VERSION "HIPBNYYYYYYYYYYYYYYYYYYYYYYYYYYYYYYYYYYYYY/4/%%%/4/'%**4YYY///"

NS_ :

BS_:

BU_:

BO_ 33 MagicCanNode1Heartbeat: 2 Vector__XXX
 SG_ MagicNode1Flags : 0|16@1+ (1,0) [0|0] "" Vector__XXX

BO_ 35 MagicCanNode2Heartbeat: 2 Vector__XXX
 SG_ MagicNode2Flags : 0|16@1+ (1,0) [0|0] "" Vector__XXX

BO_ 37 MagicCanNode3Heartbeat: 2 Vector__XXX
 SG_ MagicNode3Flags : 0|16@1+ (1,0) [0|0] "" Vector__XXX

BO_ 39 FrameFaultHeartbeat: 2 Vector__XXX
 SG_ FrameFaultFlags : 0|16@1+ (1,0) [0|0] "" Vector__XXX

BO_ 46 DriveControlsHeartbeat: 2 Vector__XXX
 SG_ DriveControlFlags : 0|16@1+ (1,0) [0|0] "" Vector__XXX

BO_ 47 MotorControllerHeartbeat: 2 Vector__XXX
 SG_ MotorControllerFlags : 0|16@1+ (1,0) [0|0] "" Vector__XXX

BO_ 49 CANMirrorHeatbeart: 2 Vector__XXX
 SG_ CANMirrorFlags : 0|16@1+ (1,0) [0|0] "" Vector__XXX

BO_ 52 RiderDisplayHeartbeat: 2 Vector__XXX
 SG_ RiderDisplayFlags : 0|16@1+ (1,0) [0|0] "" Vector__XXX

BO_ 58 BIM1Heartbeat: 2 Vector__XXX
 SG_ BIM1Flags : 0|16@1+ (1,0) [0|0] "" Vector__XXX

BO_ 60 BIM2Heartbeat: 2 Vector__XXX
 SG_ BIM2Flags : 0|16@1+ (1,0) [0|0] "" Vector__XXX

BO_ 62 BIM3Heartbeat: 2 Vector__XXX
 SG_ BIM3Flags : 0|16@1+ (1,0) [0|0] "" Vector__XXX

BO_ 66 BIM5Heartbeat: 2 Vector__XXX
 SG_ BIM5Flags : 0|16@1+ (1,0) [0|0] "" Vector__XXX

BO_ 68 BIM6Heartbeat: 2 Vector__XXX
 SG_ BIM6Flags : 0|16@1+ (1,0) [0|0] "" Vector__XXX

BO_ 70 BIM7Heartbeat: 2 Vector__XXX
 SG_ BIM7Flags : 0|16@1+ (1,0) [0|0] "" Vector__XXX

BO_ 72 BIM8Heartbeat: 2 Vector__XXX
 SG_ BIM8Flags : 0|16@1+ (1,0) [0|0] "" Vector__XXX

BO_ 74 BIM9Heartbeat: 2 Vector__XXX
 SG_ BIM9Flags : 0|16@1+ (1,0) [0|0] "" Vector__XXX

BO_ 76 BIM10Heartbeat: 2 Vector__XXX
 SG_ BIM10Flags : 0|16@1+ (1,0) [0|0] "" Vector__XXX

BO_ 78 BIM11Heartbeat: 2 Vector__XXX
 SG_ BIM11Flags : 0|16@1+ (1,0) [0|0] "" Vector__XXX

BO_ 80 BIM12Heartbeat: 2 Vector__XXX
 SG_ BIM12Flags : 0|16@1+ (1,0) [0|0] "" Vector__XXX

BO_ 256 FrameFaultDetectionStatus: 5 Vector__XXX
 SG_ EstimatedPackFrameResistance : 0|32@1- (1,0) [0|0] "(ohms)" Vector__XXX
 SG_ FrameFaultAlarmStatus : 32|8@1+ (1,0) [0|0] "" Vector__XXX

BO_ 257 FrontBrakePressure: 2 Vector__XXX
 SG_ FrontBrakePressure : 0|16@1+ (1,0) [0|0] "(kPa)" Vector__XXX

BO_ 258 RearBrakePressure: 2 Vector__XXX
 SG_ RearBrakePressure : 0|16@1+ (1,0) [0|0] "(kPa)" Vector__XXX

BO_ 259 FrontSuspensionTravel: 2 Vector__XXX
 SG_ FrontSuspensionPosition : 0|16@1+ (1,0) [0|0] "(%)" Vector__XXX

BO_ 260 RearSuspensionTravel: 2 Vector__XXX
 SG_ RearSuspensionPosition : 0|16@1+ (1,0) [0|0] "(%)" Vector__XXX

BO_ 261 BusSupplyCurrent12V: 0 Vector__XXX

BO_ 262 BusVoltage12V: 2 Vector__XXX
 SG_ BusVoltage12V : 0|16@1+ (1,0) [0|0] "(mv)" Vector__XXX

BO_ 263 PostMotorCoolantTemp: 2 Vector__XXX
 SG_ PostMotorCoolantTemp : 0|16@1- (1,0) [0|0] "(d°C)" Vector__XXX

BO_ 264 PostControllerCoolantTemp: 2 Vector__XXX
 SG_ PostControllerCoolantTemp : 0|16@1- (1,0) [0|0] "(d°C)" Vector__XXX

BO_ 265 RadiatorCoolSideCoolantTemp: 2 Vector__XXX
 SG_ RadiatorCoolSideCoolantTemp : 0|16@1- (1,0) [0|0] "(d°C)" Vector__XXX

BO_ 266 AmbientTemp: 2 Vector__XXX
 SG_ AmbientTemp : 0|16@1- (1,0) [0|0] "(d°C)" Vector__XXX

BO_ 267 GPSLatAndValidityStatus: 8 Vector__XXX
 SG_ GPSLatitude : 0|56@1- (1,0) [0|0] "" Vector__XXX
 SG_ GPSValidityStatus : 56|8@1+ (1,0) [0|0] "" Vector__XXX

BO_ 268 GPSLongitude: 7 Vector__XXX
 SG_ GPSLongitude : 0|56@1- (1,0) [0|0] "" Vector__XXX

BO_ 269 GPSAltitudeAndAccuracy: 8 Vector__XXX
 SG_ GPSAltitude : 0|48@1- (1,0) [0|0] "(decimeters)" Vector__XXX
 SG_ PositionDOP : 48|16@1+ (1,0) [0|0] "" Vector__XXX

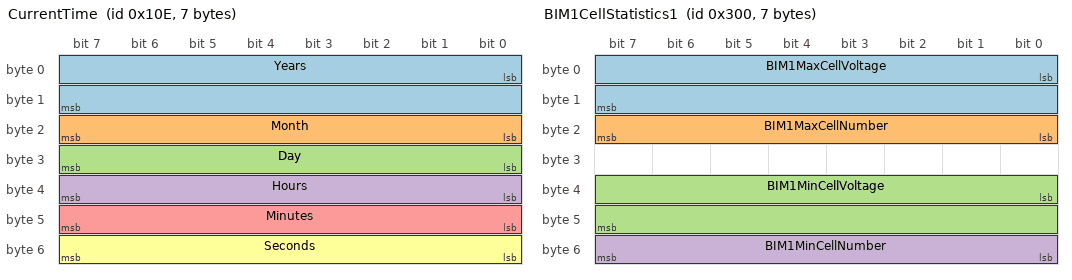
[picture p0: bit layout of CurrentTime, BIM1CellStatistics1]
BO_ 270 CurrentTime: 7 Vector__XXX
 SG_ Years : 0|16@1+ (1,0) [0|0] "" Vector__XXX
 SG_ Month : 16|8@1+ (1,0) [0|0] "" Vector__XXX
 SG_ Day : 24|8@1+ (1,0) [0|0] "" Vector__XXX
 SG_ Hours : 32|8@1+ (1,0) [0|0] "" Vector__XXX
 SG_ Minutes : 40|8@1+ (1,0) [0|0] "" Vector__XXX
 SG_ Seconds : 48|8@1+ (1,0) [0|0] "" Vector__XXX

BO_ 271 IMUAccelerationMeasurement: 6 Vector__XXX
 SG_ XAxisAcceleration : 0|16@1- (1,0) [0|0] "(?)" Vector__XXX
 SG_ YAxisAcceleration : 16|16@1- (1,0) [0|0] "(?)" Vector__XXX
 SG_ ZAxisAcceleration : 32|16@1- (1,0) [0|0] "(?)" Vector__XXX

BO_ 272 IMUGyroMeasurement: 6 Vector__XXX
 SG_ XAxisRoll : 0|16@1- (1,0) [0|0] "(?)" Vector__XXX
 SG_ YAxisRoll : 16|16@1- (1,0) [0|0] "(?)" Vector__XXX
 SG_ ZAxisRoll : 32|16@1- (1,0) [0|0] "(?)" Vector__XXX

BO_ 273 MotorPlateTemp: 8 Vector__XXX
 SG_ MotorPlateTemp1 : 0|16@1- (1,0) [0|0] "(dºC)" Vector__XXX
 SG_ MotorPlateTemp2 : 16|16@1- (1,0) [0|0] "(dºC)" Vector__XXX

BO_ 768 BIM1CellStatistics1: 7 Vector__XXX
 SG_ BIM1MaxCellVoltage : 0|16@1+ (1,0) [0|0] "(mV)" Vector__XXX
 SG_ BIM1MaxCellNumber : 16|8@1+ (1,0) [0|0] "" Vector__XXX
 SG_ BIM1MinCellVoltage : 32|16@1+ (1,0) [0|0] "(mV)" Vector__XXX
 SG_ BIM1MinCellNumber : 48|8@1+ (1,0) [0|0] "" Vector__XXX

BO_ 769 BIM1CellStatistics2: 5 Vector__XXX
 SG_ BIM1AvgCellVoltage : 0|16@1+ (1,0) [0|0] "(mV)" Vector__XXX
 SG_ BIM1StdevCellVoltage : 16|16@1+ (1,0) [0|0] "(mV)" Vector__XXX
 SG_ BIM1NumberBalancingCells : 32|8@1+ (1,0) [0|0] "" Vector__XXX

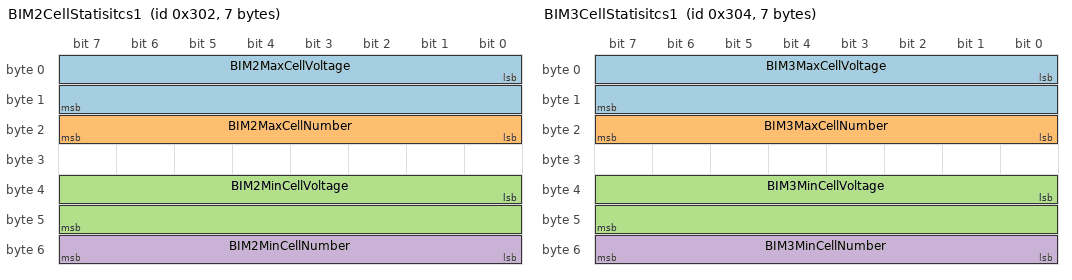
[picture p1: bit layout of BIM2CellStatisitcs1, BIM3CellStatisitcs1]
BO_ 770 BIM2CellStatisitcs1: 7 Vector__XXX
 SG_ BIM2MaxCellVoltage : 0|16@1+ (1,0) [0|0] "(mV)" Vector__XXX
 SG_ BIM2MaxCellNumber : 16|8@1+ (1,0) [0|0] "" Vector__XXX
 SG_ BIM2MinCellVoltage : 32|16@1+ (1,0) [0|0] "(mV)" Vector__XXX
 SG_ BIM2MinCellNumber : 48|8@1+ (1,0) [0|0] "" Vector__XXX

BO_ 771 BIM2CellStatistics2: 5 Vector__XXX
 SG_ BIM2AvgCellVoltage : 0|16@1+ (1,0) [0|0] "(mV)" Vector__XXX
 SG_ BIM2StdevCellVoltage : 16|16@1+ (1,0) [0|0] "(mV)" Vector__XXX
 SG_ BIM2NumberBalancingCells : 32|8@1+ (1,0) [0|0] "" Vector__XXX

BO_ 772 BIM3CellStatisitcs1: 7 Vector__XXX
 SG_ BIM3MaxCellVoltage : 0|16@1+ (1,0) [0|0] "(mV)" Vector__XXX
 SG_ BIM3MaxCellNumber : 16|8@1+ (1,0) [0|0] "" Vector__XXX
 SG_ BIM3MinCellVoltage : 32|16@1+ (1,0) [0|0] "(mV)" Vector__XXX
 SG_ BIM3MinCellNumber : 48|8@1+ (1,0) [0|0] "" Vector__XXX

BO_ 773 BIM3CellStatistics2: 5 Vector__XXX
 SG_ BIM3AvgCellVoltage : 0|16@1+ (1,0) [0|0] "(mV)" Vector__XXX
 SG_ BIM3StdevCellVoltage : 16|16@1+ (1,0) [0|0] "(mV)" Vector__XXX
 SG_ BIM3NumberBalancingCells : 32|8@1+ (1,0) [0|0] "" Vector__XXX

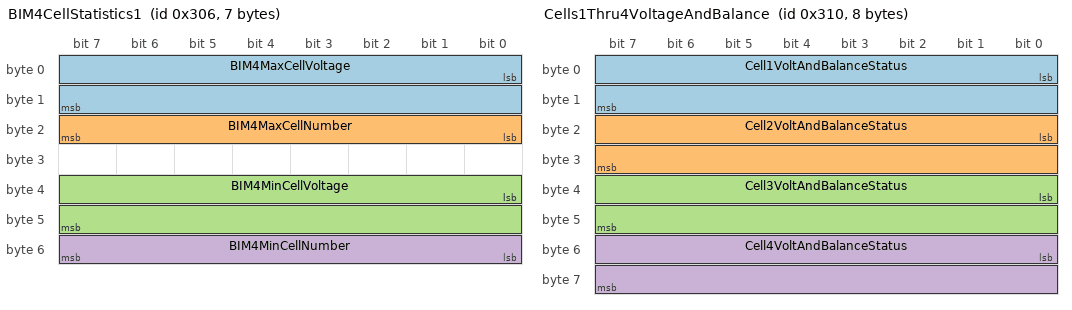
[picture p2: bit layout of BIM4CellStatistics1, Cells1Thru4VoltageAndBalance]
BO_ 774 BIM4CellStatistics1: 7 Vector__XXX
 SG_ BIM4MaxCellVoltage : 0|16@1+ (1,0) [0|0] "(mV)" Vector__XXX
 SG_ BIM4MaxCellNumber : 16|8@1+ (1,0) [0|0] "" Vector__XXX
 SG_ BIM4MinCellVoltage : 32|16@1+ (1,0) [0|0] "(mV)" Vector__XXX
 SG_ BIM4MinCellNumber : 48|8@1+ (1,0) [0|0] "" Vector__XXX

BO_ 775 BIM4CellStatistics2: 5 Vector__XXX
 SG_ BIM4AvgCellVoltage : 0|16@1+ (1,0) [0|0] "(mV)" Vector__XXX
 SG_ BIM4StdevCellVoltage : 16|16@1+ (1,0) [0|0] "(mV)" Vector__XXX
 SG_ BIM4NumberBalancingCells : 32|8@1+ (1,0) [0|0] "" Vector__XXX

BO_ 784 Cells1Thru4VoltageAndBalance: 8 Vector__XXX
 SG_ Cell1VoltAndBalanceStatus : 0|16@1- (1,0) [0|0] "(mV and sign)" Vector__XXX
 SG_ Cell2VoltAndBalanceStatus : 16|16@1- (1,0) [0|0] "(mV and sign)" Vector__XXX
 SG_ Cell3VoltAndBalanceStatus : 32|16@1- (1,0) [0|0] "(mV and sign)" Vector__XXX
 SG_ Cell4VoltAndBalanceStatus : 48|16@1- (1,0) [0|0] "(mV and sign)" Vector__XXX

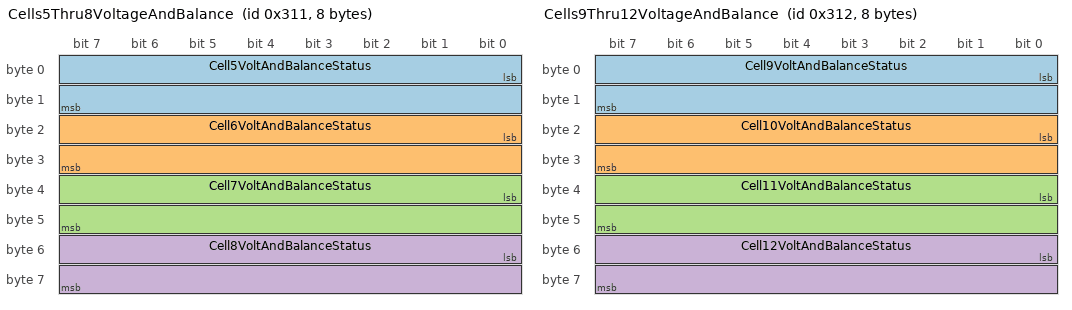
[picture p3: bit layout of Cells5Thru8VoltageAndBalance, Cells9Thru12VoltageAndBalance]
BO_ 785 Cells5Thru8VoltageAndBalance: 8 Vector__XXX
 SG_ Cell5VoltAndBalanceStatus : 0|16@1- (1,0) [0|0] "(mV and sign)" Vector__XXX
 SG_ Cell6VoltAndBalanceStatus : 16|16@1- (1,0) [0|0] "(mV and sign)" Vector__XXX
 SG_ Cell7VoltAndBalanceStatus : 32|16@1- (1,0) [0|0] "(mV and sign)" Vector__XXX
 SG_ Cell8VoltAndBalanceStatus : 48|16@1- (1,0) [0|0] "(mV and sign)" Vector__XXX

BO_ 786 Cells9Thru12VoltageAndBalance: 8 Vector__XXX
 SG_ Cell9VoltAndBalanceStatus : 0|16@1- (1,0) [0|0] "(mV and sign)" Vector__XXX
 SG_ Cell10VoltAndBalanceStatus : 16|16@1- (1,0) [0|0] "(mV and sign)" Vector__XXX
 SG_ Cell11VoltAndBalanceStatus : 32|16@1- (1,0) [0|0] "(mV and sign)" Vector__XXX
 SG_ Cell12VoltAndBalanceStatus : 48|16@1- (1,0) [0|0] "(mV and sign)" Vector__XXX

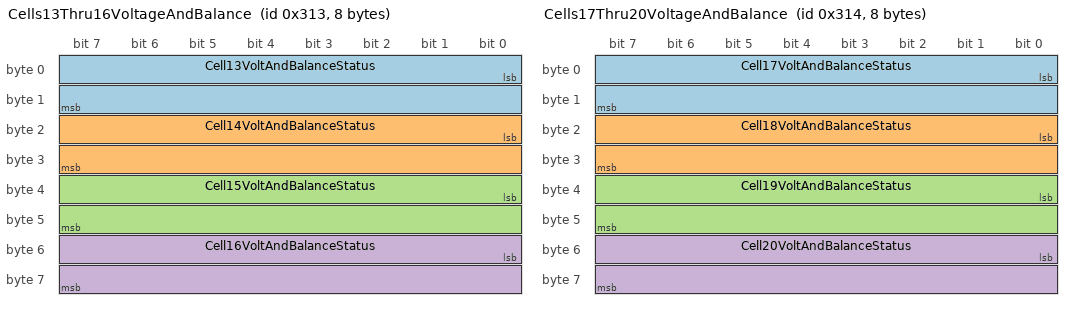
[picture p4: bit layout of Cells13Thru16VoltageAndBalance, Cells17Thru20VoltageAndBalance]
BO_ 787 Cells13Thru16VoltageAndBalance: 8 Vector__XXX
 SG_ Cell13VoltAndBalanceStatus : 0|16@1- (1,0) [0|0] "(mV and sign)" Vector__XXX
 SG_ Cell14VoltAndBalanceStatus : 16|16@1- (1,0) [0|0] "(mV and sign)" Vector__XXX
 SG_ Cell15VoltAndBalanceStatus : 32|16@1- (1,0) [0|0] "(mV and sign)" Vector__XXX
 SG_ Cell16VoltAndBalanceStatus : 48|16@1- (1,0) [0|0] "(mV and sign)" Vector__XXX

BO_ 788 Cells17Thru20VoltageAndBalance: 8 Vector__XXX
 SG_ Cell17VoltAndBalanceStatus : 0|16@1- (1,0) [0|0] "(mV and sign)" Vector__XXX
 SG_ Cell18VoltAndBalanceStatus : 16|16@1- (1,0) [0|0] "(mV and sign)" Vector__XXX
 SG_ Cell19VoltAndBalanceStatus : 32|16@1- (0,0) [0|0] "(mV and sign)" Vector__XXX
 SG_ Cell20VoltAndBalanceStatus : 48|16@1- (1,0) [0|0] "(mV and sign)" Vector__XXX

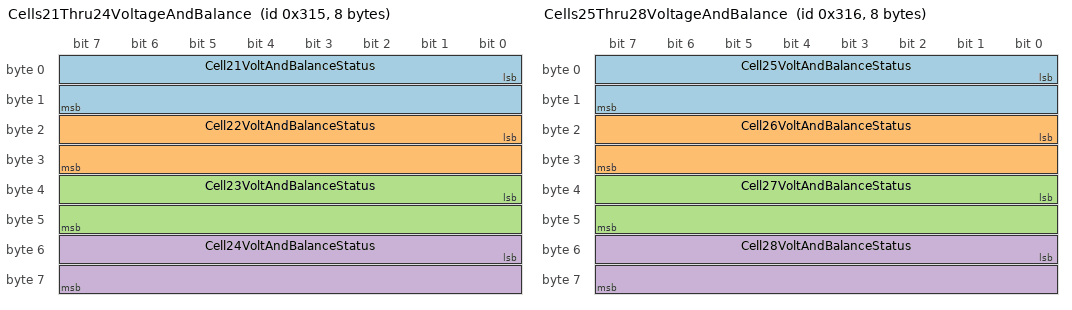
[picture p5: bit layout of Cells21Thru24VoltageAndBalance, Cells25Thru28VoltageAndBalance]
BO_ 789 Cells21Thru24VoltageAndBalance: 8 Vector__XXX
 SG_ Cell21VoltAndBalanceStatus : 0|16@1- (1,0) [0|0] "(mV and sign)" Vector__XXX
 SG_ Cell22VoltAndBalanceStatus : 16|16@1- (1,0) [0|0] "(mV and sign)" Vector__XXX
 SG_ Cell23VoltAndBalanceStatus : 32|16@1- (1,0) [0|0] "(mV and sign)" Vector__XXX
 SG_ Cell24VoltAndBalanceStatus : 48|16@1- (1,0) [0|0] "(mV and sign)" Vector__XXX

BO_ 790 Cells25Thru28VoltageAndBalance: 8 Vector__XXX
 SG_ Cell25VoltAndBalanceStatus : 0|16@1- (1,0) [0|0] "(mV and sign)" Vector__XXX
 SG_ Cell26VoltAndBalanceStatus : 16|16@1- (1,0) [0|0] "(mV and sign)" Vector__XXX
 SG_ Cell27VoltAndBalanceStatus : 32|16@1- (1,0) [0|0] "(mV and sign)" Vector__XXX
 SG_ Cell28VoltAndBalanceStatus : 48|16@1- (1,0) [0|0] "(mV and sign)" Vector__XXX

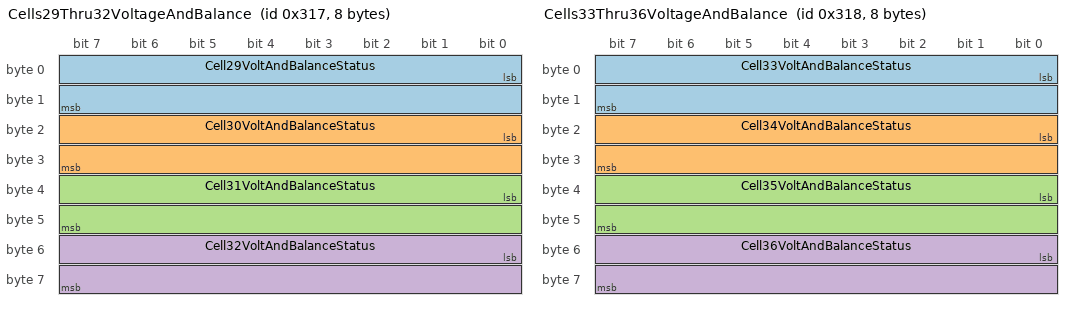
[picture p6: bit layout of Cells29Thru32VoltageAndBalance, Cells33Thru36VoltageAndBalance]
BO_ 791 Cells29Thru32VoltageAndBalance: 8 Vector__XXX
 SG_ Cell29VoltAndBalanceStatus : 0|16@1- (1,0) [0|0] "(mV and sign)" Vector__XXX
 SG_ Cell30VoltAndBalanceStatus : 16|16@1- (1,0) [0|0] "(mV and sign)" Vector__XXX
 SG_ Cell31VoltAndBalanceStatus : 32|16@1- (1,0) [0|0] "(mV and sign)" Vector__XXX
 SG_ Cell32VoltAndBalanceStatus : 48|16@1- (1,0) [0|0] "(mV and sign)" Vector__XXX

BO_ 792 Cells33Thru36VoltageAndBalance: 8 Vector__XXX
 SG_ Cell33VoltAndBalanceStatus : 0|16@1- (1,0) [0|0] "(mV and sign)" Vector__XXX
 SG_ Cell34VoltAndBalanceStatus : 16|16@1- (1,0) [0|0] "(mV and sign)" Vector__XXX
 SG_ Cell35VoltAndBalanceStatus : 32|16@1- (1,0) [0|0] "(mV and sign)" Vector__XXX
 SG_ Cell36VoltAndBalanceStatus : 48|16@1- (1,0) [0|0] "(mV and sign)" Vector__XXX

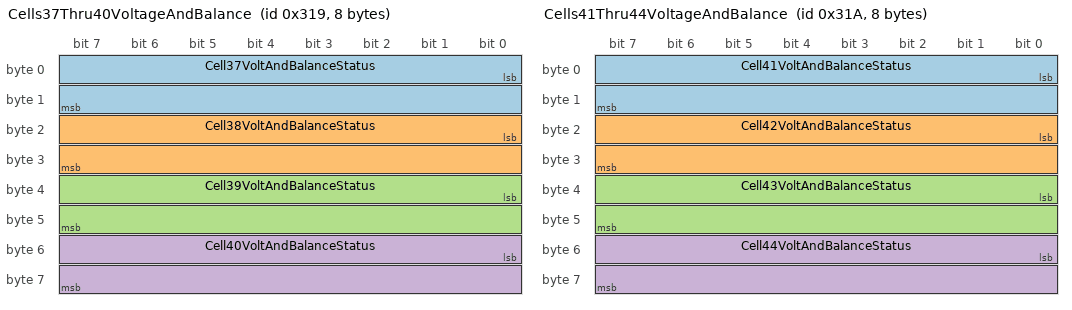
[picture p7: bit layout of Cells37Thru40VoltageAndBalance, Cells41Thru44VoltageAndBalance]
BO_ 793 Cells37Thru40VoltageAndBalance: 8 Vector__XXX
 SG_ Cell37VoltAndBalanceStatus : 0|16@1- (1,0) [0|0] "(mV and sign)" Vector__XXX
 SG_ Cell38VoltAndBalanceStatus : 16|16@1- (1,0) [0|0] "(mV and sign)" Vector__XXX
 SG_ Cell39VoltAndBalanceStatus : 32|16@1- (1,0) [0|0] "(mV and sign)" Vector__XXX
 SG_ Cell40VoltAndBalanceStatus : 48|16@1- (1,0) [0|0] "(mV and sign)" Vector__XXX

BO_ 794 Cells41Thru44VoltageAndBalance: 8 Vector__XXX
 SG_ Cell41VoltAndBalanceStatus : 0|16@1- (1,0) [0|0] "(mV and sign)" Vector__XXX
 SG_ Cell42VoltAndBalanceStatus : 16|16@1- (1,0) [0|0] "(mV and sign)" Vector__XXX
 SG_ Cell43VoltAndBalanceStatus : 32|16@1- (1,0) [0|0] "(mV and sign)" Vector__XXX
 SG_ Cell44VoltAndBalanceStatus : 48|16@1- (1,0) [0|0] "(mV and sign)" Vector__XXX

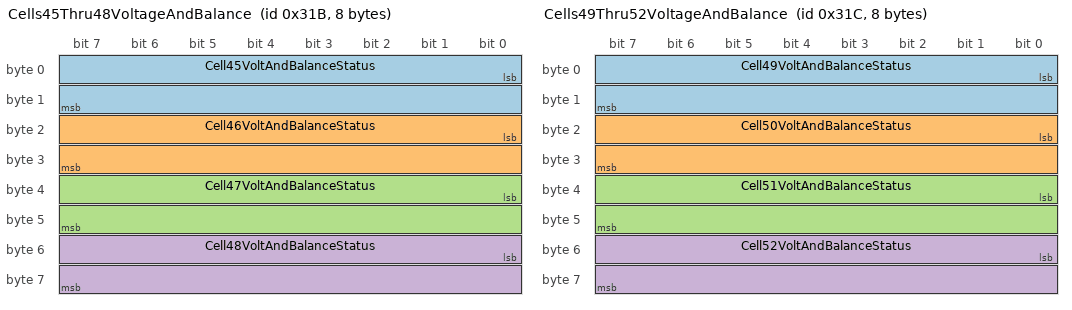
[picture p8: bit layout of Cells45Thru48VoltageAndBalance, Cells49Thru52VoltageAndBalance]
BO_ 795 Cells45Thru48VoltageAndBalance: 8 Vector__XXX
 SG_ Cell45VoltAndBalanceStatus : 0|16@1- (1,0) [0|0] "(mV and sign)" Vector__XXX
 SG_ Cell46VoltAndBalanceStatus : 16|16@1- (1,0) [0|0] "(mV and sign)" Vector__XXX
 SG_ Cell47VoltAndBalanceStatus : 32|16@1- (1,0) [0|0] "(mV and sign)" Vector__XXX
 SG_ Cell48VoltAndBalanceStatus : 48|16@1- (1,0) [0|0] "(mV and sign)" Vector__XXX

BO_ 796 Cells49Thru52VoltageAndBalance: 8 Vector__XXX
 SG_ Cell49VoltAndBalanceStatus : 0|16@1- (1,0) [0|0] "(mV and sign)" Vector__XXX
 SG_ Cell50VoltAndBalanceStatus : 16|16@1- (1,0) [0|0] "(mV and sign)" Vector__XXX
 SG_ Cell51VoltAndBalanceStatus : 32|16@1- (1,0) [0|0] "(mV and sign)" Vector__XXX
 SG_ Cell52VoltAndBalanceStatus : 48|16@1- (1,0) [0|0] "(mV and sign)" Vector__XXX

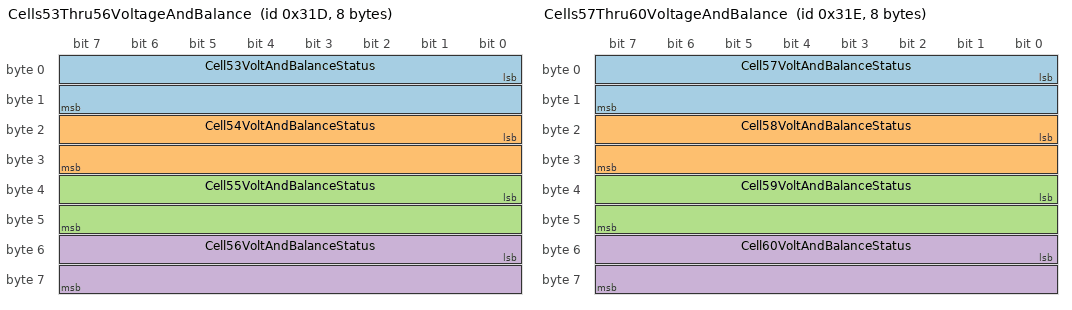
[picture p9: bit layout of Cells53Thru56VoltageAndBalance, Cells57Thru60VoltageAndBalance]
BO_ 797 Cells53Thru56VoltageAndBalance: 8 Vector__XXX
 SG_ Cell53VoltAndBalanceStatus : 0|16@1- (1,0) [0|0] "(mV and sign)" Vector__XXX
 SG_ Cell54VoltAndBalanceStatus : 16|16@1- (1,0) [0|0] "(mV and sign)" Vector__XXX
 SG_ Cell55VoltAndBalanceStatus : 32|16@1- (1,0) [0|0] "(mV and sign)" Vector__XXX
 SG_ Cell56VoltAndBalanceStatus : 48|16@1- (1,0) [0|0] "(mV and sign)" Vector__XXX

BO_ 798 Cells57Thru60VoltageAndBalance: 8 Vector__XXX
 SG_ Cell57VoltAndBalanceStatus : 0|16@1- (1,0) [0|0] "(mV and sign)" Vector__XXX
 SG_ Cell58VoltAndBalanceStatus : 16|16@1- (1,0) [0|0] "(mV and sign)" Vector__XXX
 SG_ Cell59VoltAndBalanceStatus : 32|16@1- (1,0) [0|0] "(mV and sign)" Vector__XXX
 SG_ Cell60VoltAndBalanceStatus : 48|16@1- (1,0) [0|0] "(mV and sign)" Vector__XXX

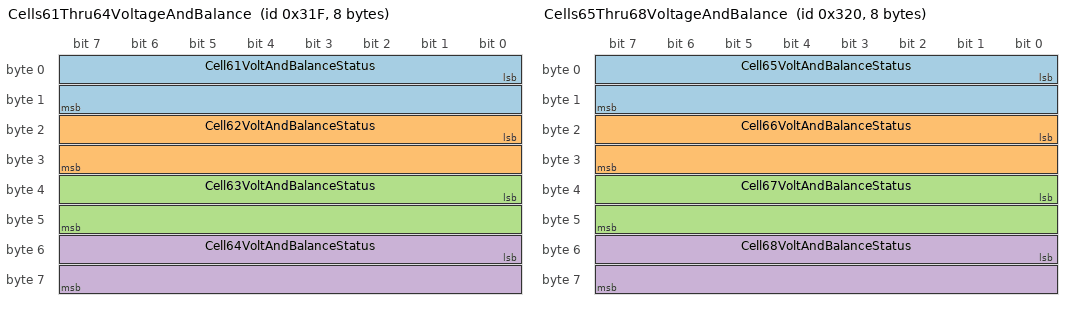
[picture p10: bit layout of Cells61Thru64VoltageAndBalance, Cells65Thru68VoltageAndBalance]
BO_ 799 Cells61Thru64VoltageAndBalance: 8 Vector__XXX
 SG_ Cell61VoltAndBalanceStatus : 0|16@1- (1,0) [0|0] "(mV and sign)" Vector__XXX
 SG_ Cell62VoltAndBalanceStatus : 16|16@1- (1,0) [0|0] "(mV and sign)" Vector__XXX
 SG_ Cell63VoltAndBalanceStatus : 32|16@1- (1,0) [0|0] "(mV and sign)" Vector__XXX
 SG_ Cell64VoltAndBalanceStatus : 48|16@1- (1,0) [0|0] "(mV and sign)" Vector__XXX

BO_ 800 Cells65Thru68VoltageAndBalance: 8 Vector__XXX
 SG_ Cell65VoltAndBalanceStatus : 0|16@1- (1,0) [0|0] "(mV and sign)" Vector__XXX
 SG_ Cell66VoltAndBalanceStatus : 16|16@1- (1,0) [0|0] "(mV and sign)" Vector__XXX
 SG_ Cell67VoltAndBalanceStatus : 32|16@1- (1,0) [0|0] "(mV and sign)" Vector__XXX
 SG_ Cell68VoltAndBalanceStatus : 48|16@1- (1,0) [0|0] "(mV and sign)" Vector__XXX

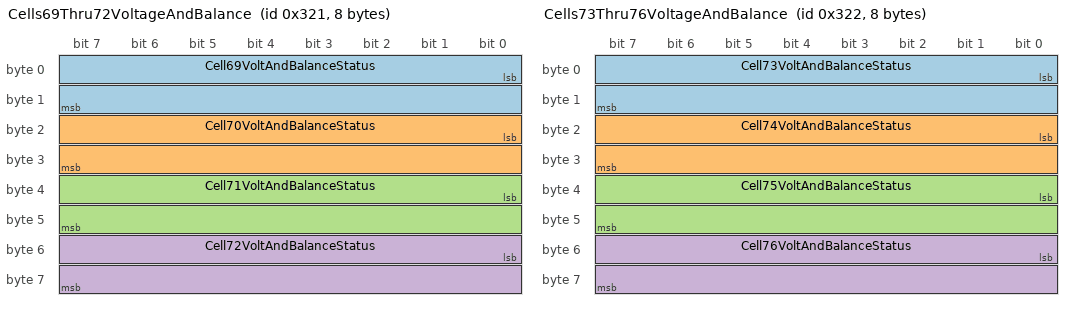
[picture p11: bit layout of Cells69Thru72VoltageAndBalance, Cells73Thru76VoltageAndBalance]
BO_ 801 Cells69Thru72VoltageAndBalance: 8 Vector__XXX
 SG_ Cell69VoltAndBalanceStatus : 0|16@1- (1,0) [0|0] "(mV and sign)" Vector__XXX
 SG_ Cell70VoltAndBalanceStatus : 16|16@1- (1,0) [0|0] "(mV and sign)" Vector__XXX
 SG_ Cell71VoltAndBalanceStatus : 32|16@1- (1,0) [0|0] "(mV and sign)" Vector__XXX
 SG_ Cell72VoltAndBalanceStatus : 48|16@1- (1,0) [0|0] "(mV and sign)" Vector__XXX

BO_ 802 Cells73Thru76VoltageAndBalance: 8 Vector__XXX
 SG_ Cell73VoltAndBalanceStatus : 0|16@1- (1,0) [0|0] "(mV and sign)" Vector__XXX
 SG_ Cell74VoltAndBalanceStatus : 16|16@1- (1,0) [0|0] "(mV and sign)" Vector__XXX
 SG_ Cell75VoltAndBalanceStatus : 32|16@1- (1,0) [0|0] "(mV and sign)" Vector__XXX
 SG_ Cell76VoltAndBalanceStatus : 48|16@1- (1,0) [0|0] "(mV and sign)" Vector__XXX

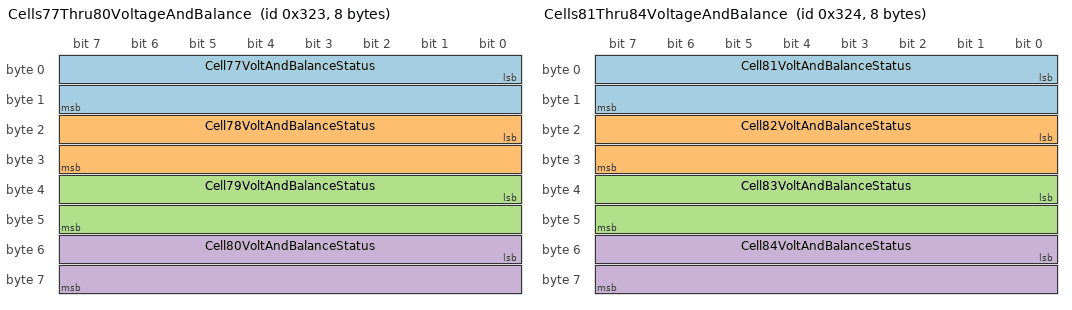
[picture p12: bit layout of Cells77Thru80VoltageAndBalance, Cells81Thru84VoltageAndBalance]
BO_ 803 Cells77Thru80VoltageAndBalance: 8 Vector__XXX
 SG_ Cell77VoltAndBalanceStatus : 0|16@1- (1,0) [0|0] "(mV and sign)" Vector__XXX
 SG_ Cell78VoltAndBalanceStatus : 16|16@1- (1,0) [0|0] "(mV and sign)" Vector__XXX
 SG_ Cell79VoltAndBalanceStatus : 32|16@1- (1,0) [0|0] "(mV and sign)" Vector__XXX
 SG_ Cell80VoltAndBalanceStatus : 48|16@1- (1,0) [0|0] "(mV and sign)" Vector__XXX

BO_ 804 Cells81Thru84VoltageAndBalance: 8 Vector__XXX
 SG_ Cell81VoltAndBalanceStatus : 0|16@1- (1,0) [0|0] "(mV and sign)" Vector__XXX
 SG_ Cell82VoltAndBalanceStatus : 16|16@1- (1,0) [0|0] "(mV and sign)" Vector__XXX
 SG_ Cell83VoltAndBalanceStatus : 32|16@1- (1,0) [0|0] "(mV and sign)" Vector__XXX
 SG_ Cell84VoltAndBalanceStatus : 48|16@1- (1,0) [0|0] "(mV and sign)" Vector__XXX

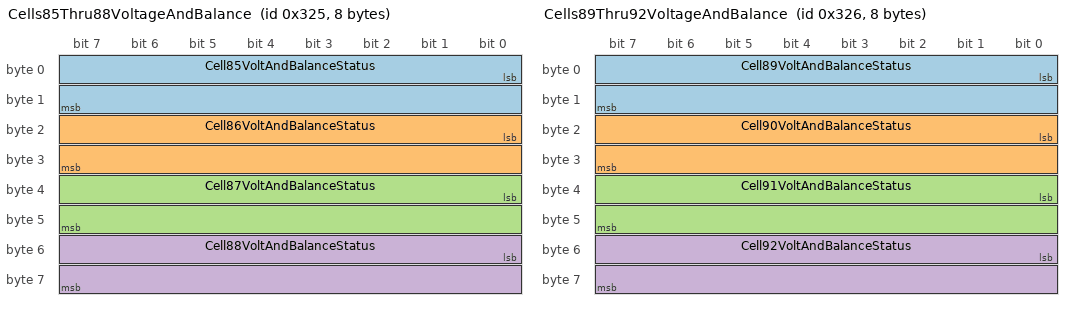
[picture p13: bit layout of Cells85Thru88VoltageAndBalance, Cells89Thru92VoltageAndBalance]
BO_ 805 Cells85Thru88VoltageAndBalance: 8 Vector__XXX
 SG_ Cell85VoltAndBalanceStatus : 0|16@1- (1,0) [0|0] "(mV and sign)" Vector__XXX
 SG_ Cell86VoltAndBalanceStatus : 16|16@1- (1,0) [0|0] "(mV and sign)" Vector__XXX
 SG_ Cell87VoltAndBalanceStatus : 32|16@1- (1,0) [0|0] "(mV and sign)" Vector__XXX
 SG_ Cell88VoltAndBalanceStatus : 48|16@1- (1,0) [0|0] "(mV and sign)" Vector__XXX

BO_ 806 Cells89Thru92VoltageAndBalance: 8 Vector__XXX
 SG_ Cell89VoltAndBalanceStatus : 0|16@1- (1,0) [0|0] "(mV and sign)" Vector__XXX
 SG_ Cell90VoltAndBalanceStatus : 16|16@1- (1,0) [0|0] "(mV and sign)" Vector__XXX
 SG_ Cell91VoltAndBalanceStatus : 32|16@1- (1,0) [0|0] "(mV and sign)" Vector__XXX
 SG_ Cell92VoltAndBalanceStatus : 48|16@1- (1,0) [0|0] "(mV and sign)" Vector__XXX

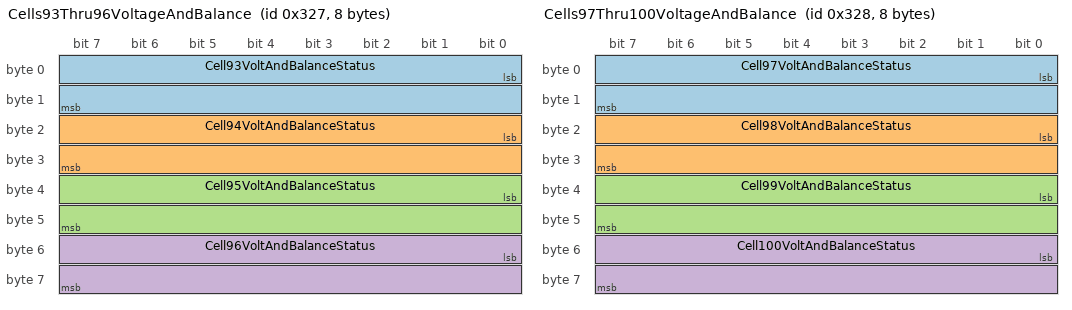
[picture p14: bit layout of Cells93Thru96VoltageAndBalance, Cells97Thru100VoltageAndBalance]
BO_ 807 Cells93Thru96VoltageAndBalance: 8 Vector__XXX
 SG_ Cell93VoltAndBalanceStatus : 0|16@1- (1,0) [0|0] "(mV and sign)" Vector__XXX
 SG_ Cell94VoltAndBalanceStatus : 16|16@1- (1,0) [0|0] "(mV and sign)" Vector__XXX
 SG_ Cell95VoltAndBalanceStatus : 32|16@1- (1,0) [0|0] "(mV and sign)" Vector__XXX
 SG_ Cell96VoltAndBalanceStatus : 48|16@1- (1,0) [0|0] "(mV and sign)" Vector__XXX

BO_ 808 Cells97Thru100VoltageAndBalance: 8 Vector__XXX
 SG_ Cell97VoltAndBalanceStatus : 0|16@1- (1,0) [0|0] "(mV and sign)" Vector__XXX
 SG_ Cell98VoltAndBalanceStatus : 16|16@1- (1,0) [0|0] "(mV and sign)" Vector__XXX
 SG_ Cell99VoltAndBalanceStatus : 32|16@1- (1,0) [0|0] "(mV and sign)" Vector__XXX
 SG_ Cell100VoltAndBalanceStatus : 48|16@1- (1,0) [0|0] "(mV and sign)" Vector__XXX

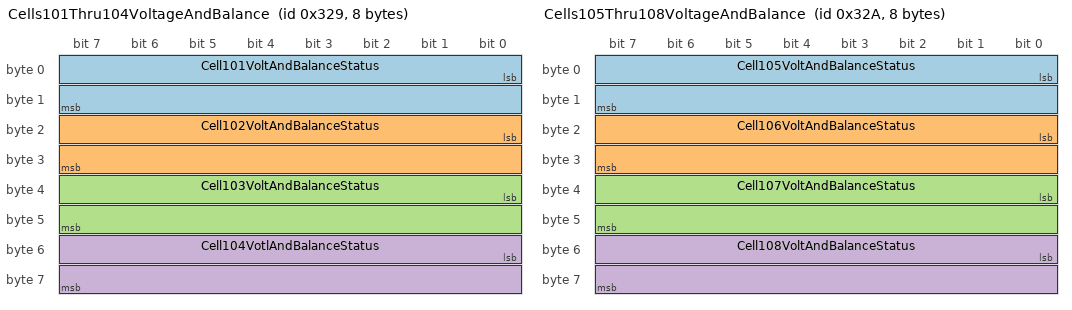
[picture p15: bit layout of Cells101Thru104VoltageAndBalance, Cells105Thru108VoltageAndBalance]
BO_ 809 Cells101Thru104VoltageAndBalance: 8 Vector__XXX
 SG_ Cell101VoltAndBalanceStatus : 0|16@1- (1,0) [0|0] "(mV and sign)" Vector__XXX
 SG_ Cell102VoltAndBalanceStatus : 16|16@1- (1,0) [0|0] "(mV and sign)" Vector__XXX
 SG_ Cell103VoltAndBalanceStatus : 32|16@1- (1,0) [0|0] "(mV and sign)" Vector__XXX
 SG_ Cell104VotlAndBalanceStatus : 48|16@1- (1,0) [0|0] "(mV and sign)" Vector__XXX

BO_ 810 Cells105Thru108VoltageAndBalance: 8 Vector__XXX
 SG_ Cell105VoltAndBalanceStatus : 0|16@1- (1,0) [0|0] "(mV and sign)" Vector__XXX
 SG_ Cell106VoltAndBalanceStatus : 16|16@1- (1,0) [0|0] "(mV and sign)" Vector__XXX
 SG_ Cell107VoltAndBalanceStatus : 32|16@1- (1,0) [0|0] "(mV and sign)" Vector__XXX
 SG_ Cell108VoltAndBalanceStatus : 48|16@1- (1,0) [0|0] "(mV and sign)" Vector__XXX

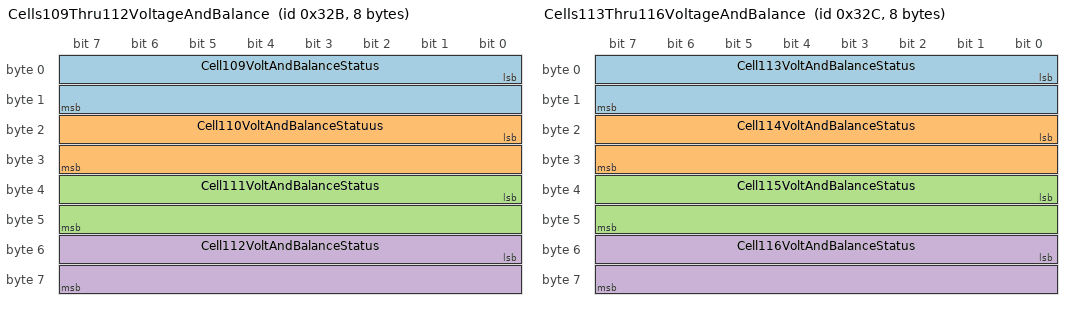
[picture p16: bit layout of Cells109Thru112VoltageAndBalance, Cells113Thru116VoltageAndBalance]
BO_ 811 Cells109Thru112VoltageAndBalance: 8 Vector__XXX
 SG_ Cell109VoltAndBalanceStatus : 0|16@1- (1,0) [0|0] "(mV and sign)" Vector__XXX
 SG_ Cell110VoltAndBalanceStatuus : 16|16@1- (1,0) [0|0] "(mV and sign)" Vector__XXX
 SG_ Cell111VoltAndBalanceStatus : 32|16@1- (1,0) [0|0] "(mV and sign)" Vector__XXX
 SG_ Cell112VoltAndBalanceStatus : 48|16@1- (1,0) [0|0] "(mV and sign)" Vector__XXX

BO_ 812 Cells113Thru116VoltageAndBalance: 8 Vector__XXX
 SG_ Cell113VoltAndBalanceStatus : 0|16@1- (1,0) [0|0] "(mV and sign)" Vector__XXX
 SG_ Cell114VoltAndBalanceStatus : 16|16@1- (1,0) [0|0] "(mV and sign)" Vector__XXX
 SG_ Cell115VoltAndBalanceStatus : 32|16@1- (1,0) [0|0] "(mV and sign)" Vector__XXX
 SG_ Cell116VoltAndBalanceStatus : 48|16@1- (1,0) [0|0] "(mV and sign)" Vector__XXX

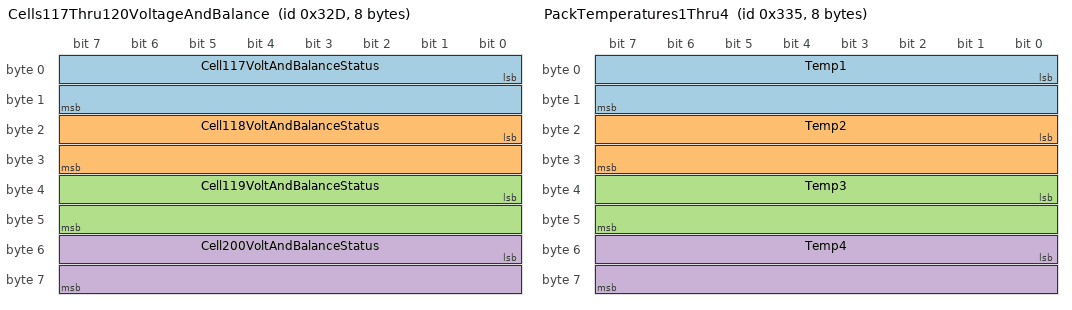
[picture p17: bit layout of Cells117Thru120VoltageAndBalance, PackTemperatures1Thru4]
BO_ 813 Cells117Thru120VoltageAndBalance: 8 Vector__XXX
 SG_ Cell117VoltAndBalanceStatus : 0|16@1- (1,0) [0|0] "(mV and sign)" Vector__XXX
 SG_ Cell118VoltAndBalanceStatus : 16|16@1- (1,0) [0|0] "(mV and sign)" Vector__XXX
 SG_ Cell119VoltAndBalanceStatus : 32|16@1- (1,0) [0|0] "(mV and sign)" Vector__XXX
 SG_ Cell200VoltAndBalanceStatus : 48|16@1- (1,0) [0|0] "(mV and sign)" Vector__XXX

BO_ 821 PackTemperatures1Thru4: 8 Vector__XXX
 SG_ Temp1 : 0|16@1- (1,0) [0|0] "(m°C)" Vector__XXX
 SG_ Temp2 : 16|16@1- (1,0) [0|0] "(m°C)" Vector__XXX
 SG_ Temp3 : 32|16@1- (1,0) [0|0] "(m°C)" Vector__XXX
 SG_ Temp4 : 48|16@1- (1,0) [0|0] "(m°C)" Vector__XXX

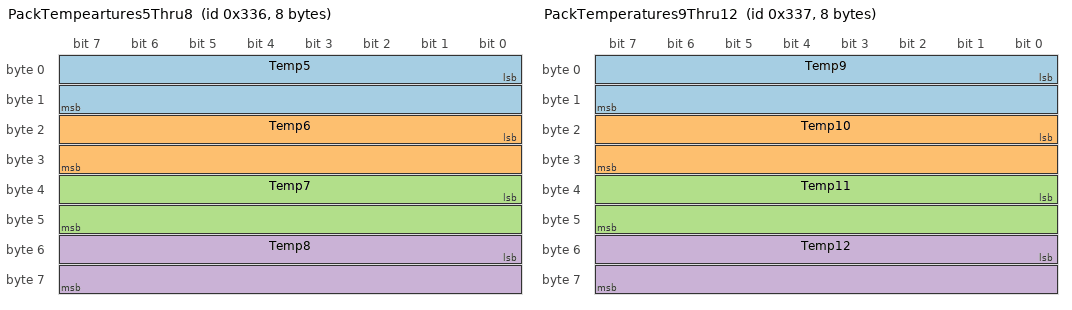
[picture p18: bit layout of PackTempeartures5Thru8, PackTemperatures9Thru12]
BO_ 822 PackTempeartures5Thru8: 8 Vector__XXX
 SG_ Temp5 : 0|16@1- (1,0) [0|0] "(m°C)" Vector__XXX
 SG_ Temp6 : 16|16@1- (1,0) [0|0] "(m°C)" Vector__XXX
 SG_ Temp7 : 32|16@1- (1,0) [0|0] "(m°C)" Vector__XXX
 SG_ Temp8 : 48|16@1- (1,0) [0|0] "(m°C)" Vector__XXX

BO_ 823 PackTemperatures9Thru12: 8 Vector__XXX
 SG_ Temp9 : 0|16@1- (1,0) [0|0] "(m°C)" Vector__XXX
 SG_ Temp10 : 16|16@1- (1,0) [0|0] "(m°C)" Vector__XXX
 SG_ Temp11 : 32|16@1- (1,0) [0|0] "(m°C)" Vector__XXX
 SG_ Temp12 : 48|16@1- (1,0) [0|0] "(m°C)" Vector__XXX

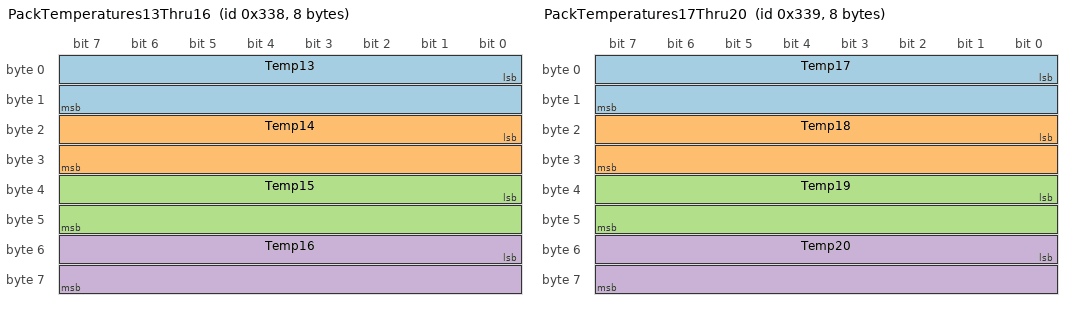
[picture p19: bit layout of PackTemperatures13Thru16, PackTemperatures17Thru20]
BO_ 824 PackTemperatures13Thru16: 8 Vector__XXX
 SG_ Temp13 : 0|16@1- (1,0) [0|0] "(mºC)" Vector__XXX
 SG_ Temp14 : 16|16@1- (1,0) [0|0] "(mºC)" Vector__XXX
 SG_ Temp15 : 32|16@1- (1,0) [0|0] "(mºC)" Vector__XXX
 SG_ Temp16 : 48|16@1- (1,0) [0|0] "(mºC)" Vector__XXX

BO_ 825 PackTemperatures17Thru20: 8 Vector__XXX
 SG_ Temp17 : 0|16@1- (1,0) [0|0] "(mºC)" Vector__XXX
 SG_ Temp18 : 16|16@1- (1,0) [0|0] "(mºC)" Vector__XXX
 SG_ Temp19 : 32|16@1- (1,0) [0|0] "(mºC)" Vector__XXX
 SG_ Temp20 : 48|16@1- (1,0) [0|0] "(mºC)" Vector__XXX

BO_ 826 PackTemperatures21Thru24: 8 Vector__XXX
 SG_ Temp21 : 0|16@1- (1,0) [0|0] "(mºC)" Vector__XXX
 SG_ Temp22 : 16|16@1- (1,0) [0|0] "(mºC)" Vector__XXX
 SG_ Temp23 : 32|16@1- (1,0) [0|0] "(mºC)" Vector__XXX
 SG_ Temp24 : 48|16@1- (1,0) [0|0] "(mºC)" Vector__XXX

BO_ 827 PackTemperatures25Thru28: 8 Vector__XXX
 SG_ Temp25 : 0|16@1- (1,0) [0|0] "(mºC)" Vector__XXX
 SG_ Temp26 : 16|16@1- (1,0) [0|0] "(mºC)" Vector__XXX
 SG_ Temp27 : 32|16@1- (1,0) [0|0] "(mºC)" Vector__XXX
 SG_ Temp28 : 48|16@1- (1,0) [0|0] "(mºC)" Vector__XXX

BO_ 828 PackTemperatures29Thru32: 8 Vector__XXX
 SG_ Temp29 : 0|16@1- (1,0) [0|0] "(mºC)" Vector__XXX
 SG_ Temp30 : 16|16@1- (1,0) [0|0] "(mºC)" Vector__XXX
 SG_ Temp31 : 32|16@1- (1,0) [0|0] "(mºC)" Vector__XXX
 SG_ Temp32 : 48|16@1- (1,0) [0|0] "(mºC)" Vector__XXX

BO_ 829 PackTemperatures33Thru36: 8 Vector__XXX
 SG_ Temp33 : 0|16@1- (1,0) [0|0] "(mºC)" Vector__XXX
 SG_ Temp34 : 16|16@1- (1,0) [0|0] "(mºC)" Vector__XXX
 SG_ Temp35 : 32|16@1- (1,0) [0|0] "(mºC)" Vector__XXX
 SG_ Temp36 : 48|16@1- (1,0) [0|0] "(mºC)" Vector__XXX

BO_ 830 PackTemperatures37Thru40: 8 Vector__XXX
 SG_ Temp37 : 0|16@1- (1,0) [0|0] "(mºC)" Vector__XXX
 SG_ Temp38 : 16|16@1- (1,0) [0|0] "(mºC)" Vector__XXX
 SG_ Temp39 : 32|16@1- (1,0) [0|0] "(mºC)" Vector__XXX
 SG_ Temp40 : 48|16@1- (1,0) [0|0] "(mºC)" Vector__XXX

SIG_VALTYPE_ 256 EstimatedPackFrameResistance : 1;
